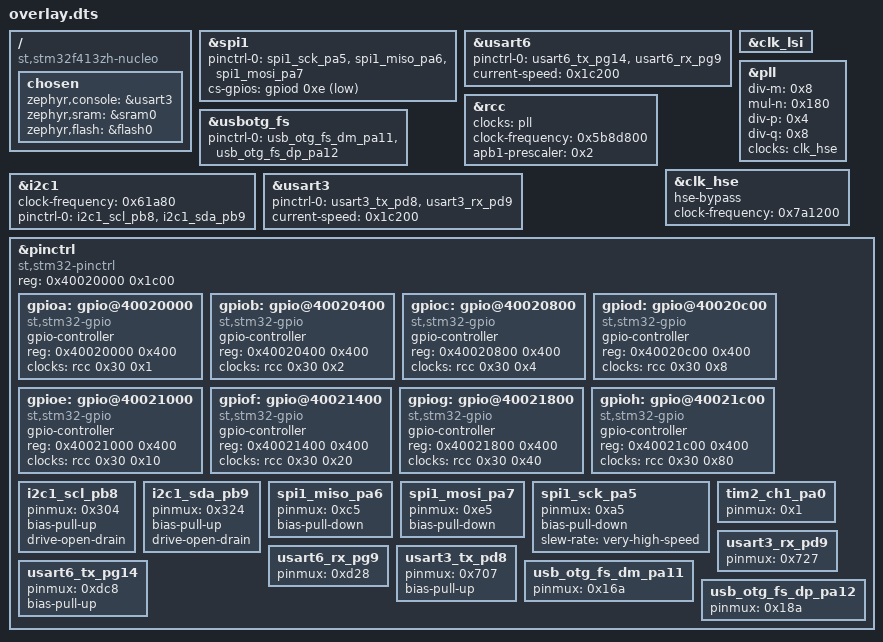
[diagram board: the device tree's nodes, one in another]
/ {
	compatible = "st,stm32f413zh-nucleo";
	chosen {
		zephyr,console = &usart3;
		zephyr,sram = &sram0;
		zephyr,flash = &flash0;
	};
};
&spi1{
	status = "okay";
	pinctrl-0 = < &spi1_sck_pa5 &spi1_miso_pa6 &spi1_mosi_pa7 >;
	pinctrl-names = "default";
	cs-gpios = < &gpiod 0xe 0x11 >;
};
&usart6{
	status = "okay";
	pinctrl-0 = < &usart6_tx_pg14 &usart6_rx_pg9 >;
	pinctrl-names = "default";
	current-speed = < 0x1c200 >;
};
&clk_lsi{
	status = "okay";
};
&rcc{
	clocks = < &pll >;
	clock-frequency = < 0x5b8d800 >;
	apb1-prescaler = < 0x2 >;
};
&pll{
	status = "okay";
	div-m = < 0x8 >;
	mul-n = < 0x180 >;
	div-p = < 0x4 >;
	div-q = < 0x8 >;
	clocks = < &clk_hse >;
};
&usbotg_fs{
	status = "okay";
	pinctrl-0 = < &usb_otg_fs_dm_pa11 &usb_otg_fs_dp_pa12 >;
	pinctrl-names = "default";
};
&i2c1{
	clock-frequency = < 0x61a80 >;
	status = "okay";
	pinctrl-0 = < &i2c1_scl_pb8 &i2c1_sda_pb9 >;
	pinctrl-names = "default";
};
&usart3{
	status = "okay";
	pinctrl-0 = < &usart3_tx_pd8 &usart3_rx_pd9 >;
	pinctrl-names = "default";
	current-speed = < 0x1c200 >;
};
&clk_hse{
	status = "okay";
	hse-bypass;
	clock-frequency = < 0x7a1200 >;
};
&pinctrl{
	compatible = "st,stm32-pinctrl";
	#address-cells = < 0x1 >;
	#size-cells = < 0x1 >;
	reg = < 0x40020000 0x1c00 >;
	gpioa: gpio@40020000 {
		compatible = "st,stm32-gpio";
		gpio-controller;
		#gpio-cells = < 0x2 >;
		reg = < 0x40020000 0x400 >;
		clocks = < &rcc 0x30 0x1 >;
	};
	gpiob: gpio@40020400 {
		compatible = "st,stm32-gpio";
		gpio-controller;
		#gpio-cells = < 0x2 >;
		reg = < 0x40020400 0x400 >;
		clocks = < &rcc 0x30 0x2 >;
	};
	gpioc: gpio@40020800 {
		compatible = "st,stm32-gpio";
		gpio-controller;
		#gpio-cells = < 0x2 >;
		reg = < 0x40020800 0x400 >;
		clocks = < &rcc 0x30 0x4 >;
	};
	gpiod: gpio@40020c00 {
		compatible = "st,stm32-gpio";
		gpio-controller;
		#gpio-cells = < 0x2 >;
		reg = < 0x40020c00 0x400 >;
		clocks = < &rcc 0x30 0x8 >;
	};
	gpioe: gpio@40021000 {
		compatible = "st,stm32-gpio";
		gpio-controller;
		#gpio-cells = < 0x2 >;
		reg = < 0x40021000 0x400 >;
		clocks = < &rcc 0x30 0x10 >;
	};
	gpiof: gpio@40021400 {
		compatible = "st,stm32-gpio";
		gpio-controller;
		#gpio-cells = < 0x2 >;
		reg = < 0x40021400 0x400 >;
		clocks = < &rcc 0x30 0x20 >;
	};
	gpiog: gpio@40021800 {
		compatible = "st,stm32-gpio";
		gpio-controller;
		#gpio-cells = < 0x2 >;
		reg = < 0x40021800 0x400 >;
		clocks = < &rcc 0x30 0x40 >;
	};
	gpioh: gpio@40021c00 {
		compatible = "st,stm32-gpio";
		gpio-controller;
		#gpio-cells = < 0x2 >;
		reg = < 0x40021c00 0x400 >;
		clocks = < &rcc 0x30 0x80 >;
	};
	i2c1_scl_pb8: i2c1_scl_pb8 {
		pinmux = < 0x304 >;
		bias-pull-up;
		drive-open-drain;
	};
	i2c1_sda_pb9: i2c1_sda_pb9 {
		pinmux = < 0x324 >;
		bias-pull-up;
		drive-open-drain;
	};
	spi1_miso_pa6: spi1_miso_pa6 {
		pinmux = < 0xc5 >;
		bias-pull-down;
	};
	spi1_mosi_pa7: spi1_mosi_pa7 {
		pinmux = < 0xe5 >;
		bias-pull-down;
	};
	spi1_sck_pa5: spi1_sck_pa5 {
		pinmux = < 0xa5 >;
		bias-pull-down;
		slew-rate = "very-high-speed";
	};
	tim2_ch1_pa0: tim2_ch1_pa0 {
		pinmux = < 0x1 >;
	};
	usart3_rx_pd9: usart3_rx_pd9 {
		pinmux = < 0x727 >;
	};
	usart6_rx_pg9: usart6_rx_pg9 {
		pinmux = < 0xd28 >;
	};
	usart3_tx_pd8: usart3_tx_pd8 {
		pinmux = < 0x707 >;
		bias-pull-up;
	};
	usart6_tx_pg14: usart6_tx_pg14 {
		pinmux = < 0xdc8 >;
		bias-pull-up;
	};
	usb_otg_fs_dm_pa11: usb_otg_fs_dm_pa11 {
		pinmux = < 0x16a >;
	};
	usb_otg_fs_dp_pa12: usb_otg_fs_dp_pa12 {
		pinmux = < 0x18a >;
	};
};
